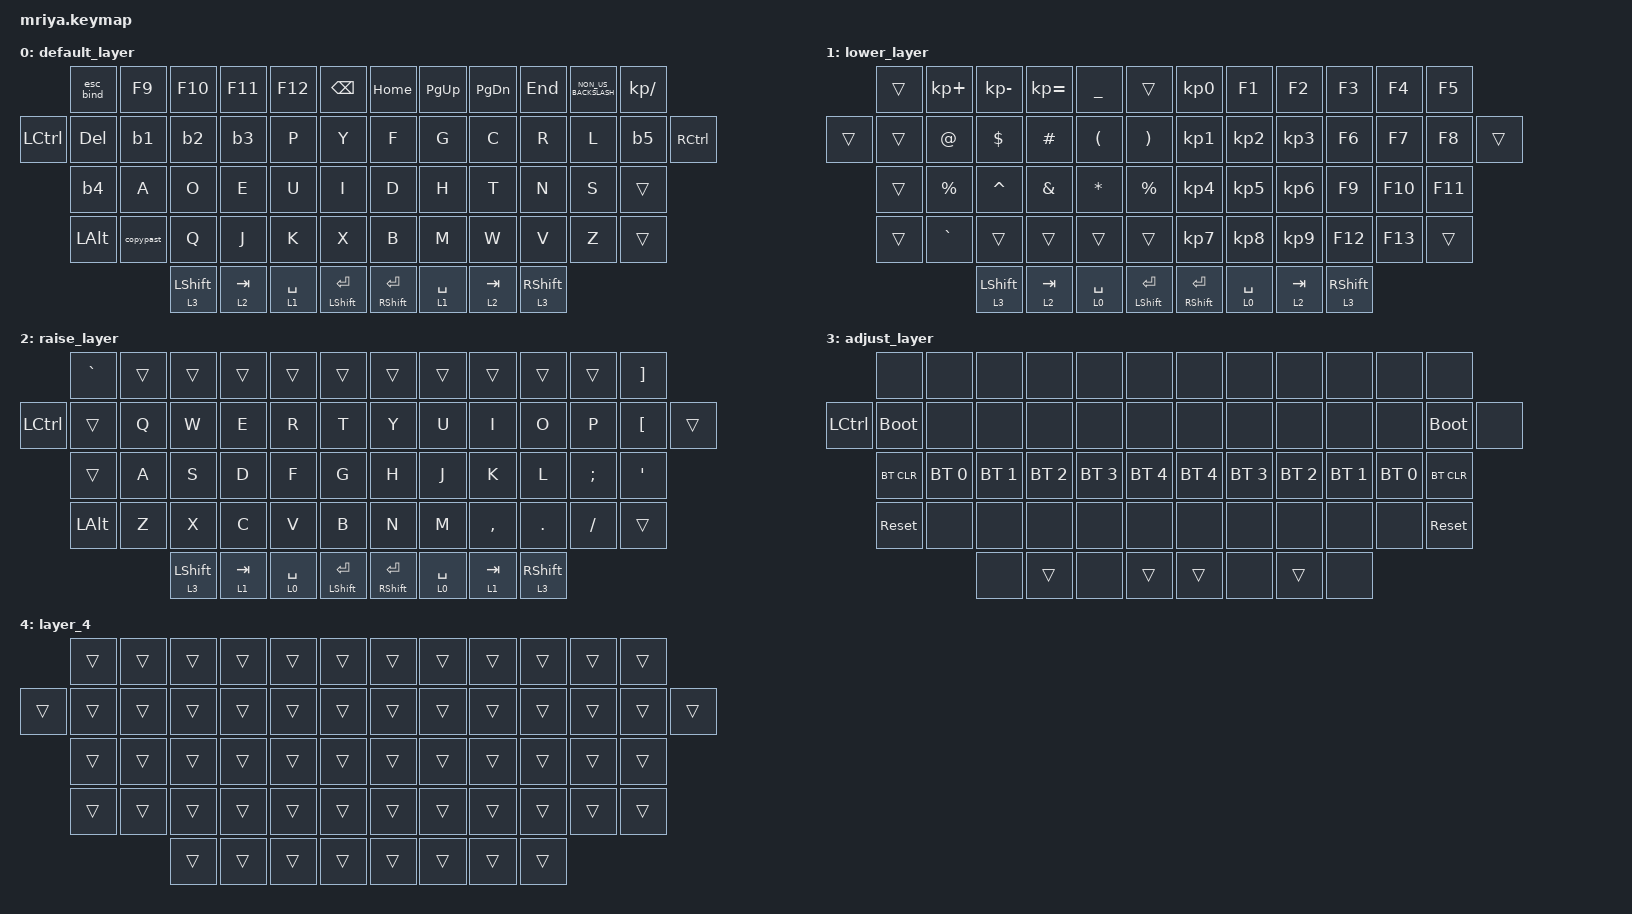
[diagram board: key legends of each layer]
/*
 * Copyright (c) 2023 Andrei Gaevskii
 *
 * SPDX-License-Identifier: MIT
 */

#include <behaviors.dtsi>
#include <dt-bindings/zmk/bt.h>
#include <dt-bindings/zmk/keys.h>

#define DEF 0
#define LWR 1
#define RSE 2
#define ADJ 3

&lt {
    quick_tap_ms = <200>;
};

&mt {
    quick_tap_ms = <200>;
};

/ {
    combos {
        compatible = "zmk,combos";

        new_combo {
            bindings = <&trans>;
            key-positions = <>;
        };
    };

    behaviors {
        esc_bind: esc_bind {
            compatible = "zmk,behavior-tap-dance";
            label = "ESC_BIND";
            #binding-cells = <0>;
            bindings =
                <&kp ESC>,
                <&kp F5>;
        };
        b1: b1 {
            compatible = "zmk,behavior-tap-dance";
            label = "B1";
            #binding-cells = <0>;
            bindings =
                <&kp SEMI>,
                <&kp COLON>;
        };
        b5: b5 {
            compatible = "zmk,behavior-tap-dance";
            label = "B5";
            #binding-cells = <0>;
            bindings =
                <&kp LESS_THAN>,
                <&kp GREATER_THAN>;
        };
        b2: b2 {
            compatible = "zmk,behavior-tap-dance";
            label = "B2";
            #binding-cells = <0>;
            bindings =
                <&kp KP_DOT>,
                <&kp KP_COMMA>;
        };
        b3: b3 {
            compatible = "zmk,behavior-tap-dance";
            label = "B3";
            #binding-cells = <0>;
            bindings =
                <&kp QUESTION>,
                <&kp EXCLAMATION>;
        };
        b4: b4 {
            compatible = "zmk,behavior-tap-dance";
            label = "B4";
            #binding-cells = <0>;
            bindings =
                <&kp DOUBLE_QUOTES>,
                <&kp SQT>;
        };
        copypast: copypast {
            compatible = "zmk,behavior-hold-tap";
            label = "COPYPAST";
            bindings =
                <&copy>,
                <&past>;

            #binding-cells = <2>;
            tapping-term-ms = <100>;
        };
    };

    macros {
        copy: copy {
            compatible = "zmk,behavior-macro";
            label = "COPY";
            #binding-cells = <0>;
            bindings =
                <&macro_press>,
                <&kp LCTRL>,
                <&macro_tap>,
                <&kp C>,
                <&macro_release>,
                <&kp LCTRL>;
        };
        past: past {
            compatible = "zmk,behavior-macro";
            label = "PAST";
            #binding-cells = <0>;
            bindings =
                <&macro_press>,
                <&kp LCTRL>,
                <&macro_tap>,
                <&kp V>,
                <&macro_release>,
                <&kp LCTRL>;
        };
    };

    keymap {
        compatible = "zmk,keymap";

        default_layer {
            bindings = <
                   &esc_bind                         &kp F9           &kp F10    &kp F11      &kp F12         &kp BACKSPACE                 &kp HOME    &kp PG_UP  &kp PAGE_DOWN            &kp END  &kp NON_US_BACKSLASH  &kp KP_SLASH
&kp LEFT_CONTROL  &kp DELETE                            &b1               &b2        &b3        &kp P                 &kp Y                    &kp F        &kp G          &kp C              &kp R                 &kp L           &b5  &kp RIGHT_CONTROL
                         &b4                          &kp A             &kp O      &kp E        &kp U                 &kp I                    &kp D        &kp H          &kp T              &kp N                 &kp S        &trans
                    &kp LALT                        &copypast             &kp Q      &kp J        &kp K                 &kp X                    &kp B        &kp M          &kp W              &kp V                 &kp Z        &trans
                                                             &lt 3 LEFT_SHIFT  &lt 2 TAB  &lt 1 SPACE  &mt LEFT_SHIFT ENTER    &mt RIGHT_SHIFT ENTER  &lt 1 SPACE      &lt 2 TAB  &lt 3 RIGHT_SHIFT
            >;
        };

        lower_layer {
            bindings = <
        &trans  &kp KP_PLUS      &kp KP_MINUS   &kp KP_EQUAL        &kp UNDERSCORE                 &trans          &kp KP_NUMBER_0           &kp F1           &kp F2             &kp F3   &kp F4   &kp F5
&trans  &trans  &kp AT_SIGN        &kp DOLLAR       &kp HASH  &kp LEFT_PARENTHESIS  &kp RIGHT_PARENTHESIS          &kp KP_NUMBER_1  &kp KP_NUMBER_2  &kp KP_NUMBER_3             &kp F6   &kp F7   &kp F8  &trans
        &trans  &kp PERCENT         &kp CARET  &kp AMPERSAND          &kp ASTERISK              &kp PRCNT          &kp KP_NUMBER_4  &kp KP_NUMBER_5  &kp KP_NUMBER_6             &kp F9  &kp F10  &kp F11
        &trans    &kp GRAVE            &trans         &trans                &trans                 &trans          &kp KP_NUMBER_7  &kp KP_NUMBER_8  &kp KP_NUMBER_9            &kp F12  &kp F13   &trans
                             &lt 3 LEFT_SHIFT      &lt 2 TAB           &lt 0 SPACE   &mt LEFT_SHIFT ENTER    &mt RIGHT_SHIFT ENTER      &lt 0 SPACE        &lt 2 TAB  &lt 3 RIGHT_SHIFT
            >;
        };

        raise_layer {
            bindings = <
                     &kp GRAVE  &trans            &trans     &trans       &trans                &trans                   &trans       &trans     &trans             &trans         &trans  &kp RIGHT_BRACKET
&kp LEFT_CONTROL        &trans   &kp Q             &kp W      &kp E        &kp R                 &kp T                    &kp Y        &kp U      &kp I              &kp O          &kp P   &kp LEFT_BRACKET  &trans
                        &trans   &kp A             &kp S      &kp D        &kp F                 &kp G                    &kp H        &kp J      &kp K              &kp L  &kp SEMICOLON            &kp SQT
                  &kp LEFT_ALT   &kp Z             &kp X      &kp C        &kp V                 &kp B                    &kp N        &kp M  &kp COMMA         &kp PERIOD      &kp SLASH             &trans
                                        &lt 3 LEFT_SHIFT  &lt 1 TAB  &lt 0 SPACE  &mt LEFT_SHIFT ENTER    &mt RIGHT_SHIFT ENTER  &lt 0 SPACE  &lt 1 TAB  &lt 3 RIGHT_SHIFT
            >;
        };

        adjust_layer {
            bindings = <
                        &none         &none         &none         &none         &none         &none           &none         &none         &none         &none         &none        &none
&kp LEFT_CONTROL  &bootloader         &none         &none         &none         &none         &none           &none         &none         &none         &none         &none  &bootloader  &none
                   &bt BT_CLR  &bt BT_SEL 0  &bt BT_SEL 1  &bt BT_SEL 2  &bt BT_SEL 3  &bt BT_SEL 4    &bt BT_SEL 4  &bt BT_SEL 3  &bt BT_SEL 2  &bt BT_SEL 1  &bt BT_SEL 0   &bt BT_CLR
                   &sys_reset         &none         &none         &none         &none         &none           &none         &none         &none         &none         &none   &sys_reset
                                                    &none        &trans         &none        &trans          &trans         &none        &trans         &none
            >;
        };

        layer_4 {
            bindings = <
        &trans  &trans  &trans  &trans  &trans  &trans    &trans  &trans  &trans  &trans  &trans  &trans
&trans  &trans  &trans  &trans  &trans  &trans  &trans    &trans  &trans  &trans  &trans  &trans  &trans  &trans
        &trans  &trans  &trans  &trans  &trans  &trans    &trans  &trans  &trans  &trans  &trans  &trans
        &trans  &trans  &trans  &trans  &trans  &trans    &trans  &trans  &trans  &trans  &trans  &trans
                        &trans  &trans  &trans  &trans    &trans  &trans  &trans  &trans
            >;
        };
    };
};
